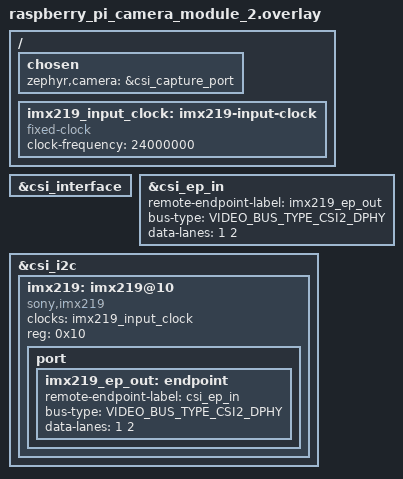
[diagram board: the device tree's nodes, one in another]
/*
 * Copyright (c) 2025 tinyVision.ai Inc.
 *
 * SPDX-License-Identifier: Apache-2.0
 */

#include <zephyr/dt-bindings/gpio/raspberrypi-csi-connector.h>
#include <zephyr/dt-bindings/video/video-interfaces.h>

/ {
	chosen {
		zephyr,camera = &csi_capture_port;
	};

	imx219_input_clock: imx219-input-clock {
		compatible = "fixed-clock";
		clock-frequency = <24000000>;
		#clock-cells = <0>;
	};
};

&csi_interface {
	status = "okay";
};

&csi_ep_in {
	remote-endpoint-label = "imx219_ep_out";
	bus-type = <VIDEO_BUS_TYPE_CSI2_DPHY>;
	data-lanes = <1 2>;
};

&csi_i2c {
	imx219: imx219@10 {
		compatible = "sony,imx219";
		clocks = <&imx219_input_clock>;
		reg = <0x10>;

		port {
			imx219_ep_out: endpoint {
				remote-endpoint-label = "csi_ep_in";
				bus-type = <VIDEO_BUS_TYPE_CSI2_DPHY>;
				data-lanes = <1 2>;
			};
		};
	};
};
